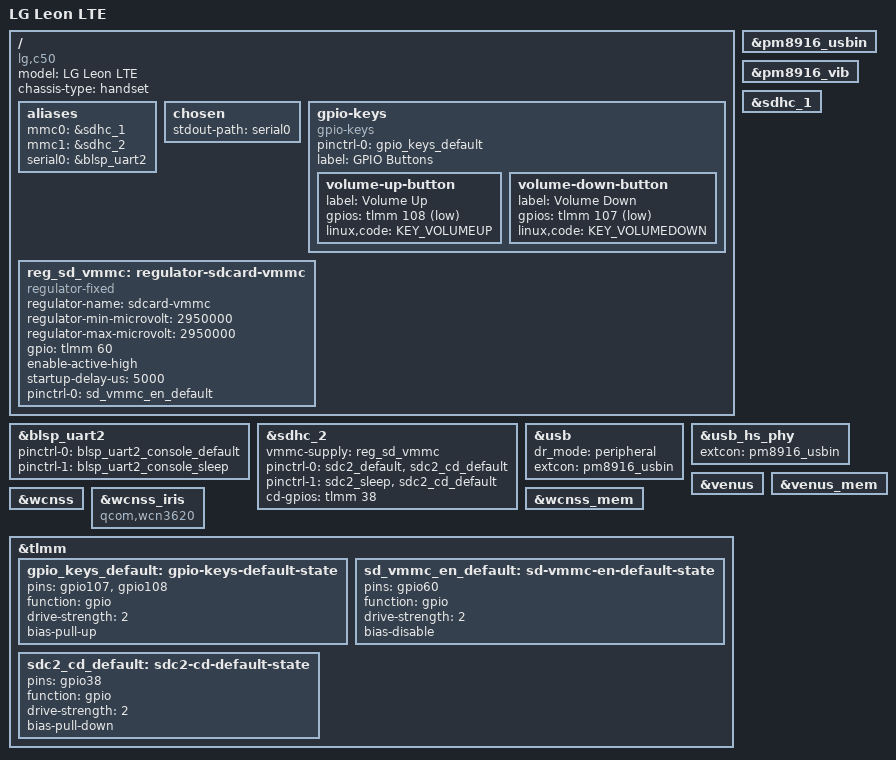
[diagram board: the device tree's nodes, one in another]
// SPDX-License-Identifier: GPL-2.0-only

/dts-v1/;

#include "msm8916-pm8916.dtsi"

#include <dt-bindings/gpio/gpio.h>

/ {
	model = "LG Leon LTE";
	compatible = "lg,c50", "qcom,msm8916";
	chassis-type = "handset";

	aliases {
		mmc0 = &sdhc_1; /* eMMC */
		mmc1 = &sdhc_2; /* SD card */
		serial0 = &blsp_uart2;
	};

	chosen {
		stdout-path = "serial0";
	};

	gpio-keys {
		compatible = "gpio-keys";

		pinctrl-0 = <&gpio_keys_default>;
		pinctrl-names = "default";

		label = "GPIO Buttons";

		volume-up-button {
			label = "Volume Up";
			gpios = <&tlmm 108 GPIO_ACTIVE_LOW>;
			linux,code = <KEY_VOLUMEUP>;
		};

		volume-down-button {
			label = "Volume Down";
			gpios = <&tlmm 107 GPIO_ACTIVE_LOW>;
			linux,code = <KEY_VOLUMEDOWN>;
		};
	};

	reg_sd_vmmc: regulator-sdcard-vmmc {
		compatible = "regulator-fixed";
		regulator-name = "sdcard-vmmc";
		regulator-min-microvolt = <2950000>;
		regulator-max-microvolt = <2950000>;

		gpio = <&tlmm 60 GPIO_ACTIVE_HIGH>;
		enable-active-high;

		startup-delay-us = <5000>;

		pinctrl-0 = <&sd_vmmc_en_default>;
		pinctrl-names = "default";
	};
};

&blsp_uart2 {
	pinctrl-0 = <&blsp_uart2_console_default>;
	pinctrl-1 = <&blsp_uart2_console_sleep>;
	pinctrl-names = "default", "sleep";
	status = "okay";
};

&pm8916_usbin {
	status = "okay";
};

&pm8916_vib {
	status = "okay";
};

&sdhc_1 {
	status = "okay";
};

&sdhc_2 {
	vmmc-supply = <&reg_sd_vmmc>;

	pinctrl-0 = <&sdc2_default &sdc2_cd_default>;
	pinctrl-1 = <&sdc2_sleep &sdc2_cd_default>;
	pinctrl-names = "default", "sleep";

	cd-gpios = <&tlmm 38 GPIO_ACTIVE_HIGH>;

	status = "okay";
};

&usb {
	dr_mode = "peripheral";
	extcon = <&pm8916_usbin>;
	status = "okay";
};

&usb_hs_phy {
	extcon = <&pm8916_usbin>;
};

&venus {
	status = "okay";
};

&venus_mem {
	status = "okay";
};

&wcnss {
	status = "okay";
};

&wcnss_iris {
	compatible = "qcom,wcn3620";
};

&wcnss_mem {
	status = "okay";
};

&tlmm {
	gpio_keys_default: gpio-keys-default-state {
		pins = "gpio107", "gpio108";
		function = "gpio";
		drive-strength = <2>;
		bias-pull-up;
	};

	sd_vmmc_en_default: sd-vmmc-en-default-state {
		pins = "gpio60";
		function = "gpio";
		drive-strength = <2>;
		bias-disable;
	};

	sdc2_cd_default: sdc2-cd-default-state {
		pins = "gpio38";
		function = "gpio";
		drive-strength = <2>;
		bias-pull-down;
	};
};
